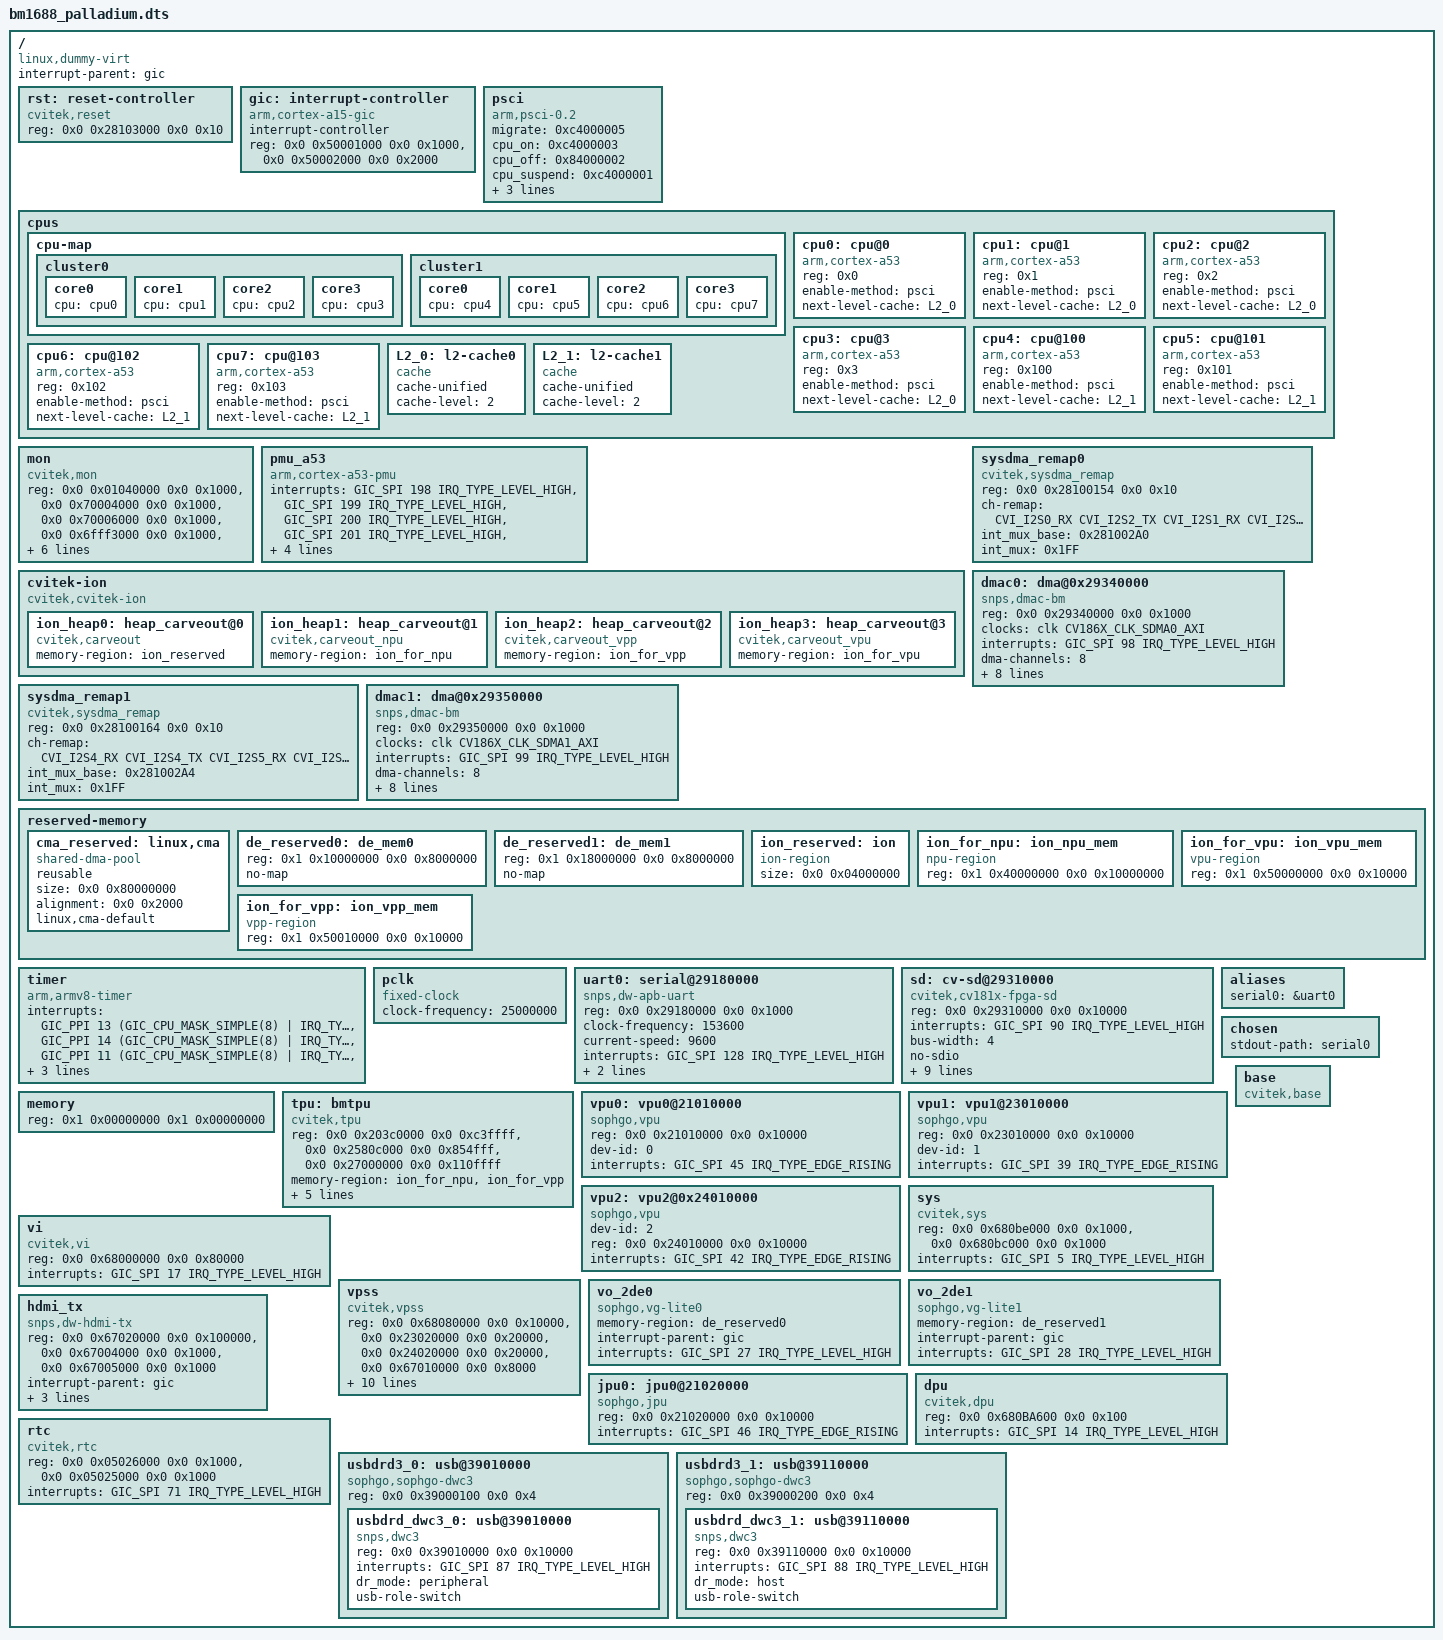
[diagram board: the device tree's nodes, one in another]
#include <dt-bindings/interrupt-controller/arm-gic.h>
#include <dt-bindings/gpio/gpio.h>
#include <dt-bindings/reset/cv186x-resets.h>
#include <dt-bindings/dma/cv186x-dmamap.h>

/dts-v1/;

/memreserve/	0x100000000 0x0000000000040000; // ATF BL31 + BL32
/memreserve/	0x200000000 0x0000000020000000; // ATF BL31 + BL32
/memreserve/	0x300000000 0x0000000003000000; // FW size: 48M

#include "soph-clocks.dtsi"
/ {
	compatible = "linux,dummy-virt";
	#size-cells = <0x2>;
	#address-cells = <0x2>;
	interrupt-parent = <&gic>;

	rst: reset-controller {
		#reset-cells = <1>;
		compatible = "cvitek,reset";
		reg = <0x0 0x28103000 0x0 0x10>;
	};

	gic: interrupt-controller {
		compatible = "arm,cortex-a15-gic";
		ranges;
		#size-cells = <0x2>;
		#address-cells = <0x2>;
		interrupt-controller;
		#interrupt-cells = <0x3>;
		reg = <0x0 0x50001000 0x0 0x1000>,
			  <0x0 0x50002000 0x0 0x2000>;
	};

	psci {
		migrate = <0xc4000005>;
		cpu_on = <0xc4000003>;
		cpu_off = <0x84000002>;
		cpu_suspend = <0xc4000001>;
		sys_poweroff = <0x84000008>;
		sys_reset = <0x84000009>;
		method = "smc";
		compatible = "arm,psci-0.2", "arm,psci";
	};

	cpus {
		#size-cells = <0x0>;
		#address-cells = <0x1>;

		cpu-map {
			cluster0 {
				core0 {
					cpu = <&cpu0>;
				};
				core1 {
					cpu = <&cpu1>;
				};
				core2 {
					cpu = <&cpu2>;
				};
				core3 {
					cpu = <&cpu3>;
				};
			};

			cluster1 {
				core0 {
					cpu = <&cpu4>;
				};
				core1 {
					cpu = <&cpu5>;
				};
				core2 {
					cpu = <&cpu6>;
				};
				core3 {
					cpu = <&cpu7>;
				};
			};
		};

		cpu0: cpu@0 {
			reg = <0x0>;
			enable-method = "psci";
			compatible = "arm,cortex-a53";
			device_type = "cpu";
			next-level-cache = <&L2_0>;
		};

		cpu1: cpu@1 {
			reg = <0x1>;
			enable-method = "psci";
			compatible = "arm,cortex-a53";
			device_type = "cpu";
			next-level-cache = <&L2_0>;
		};

		cpu2: cpu@2 {
			reg = <0x2>;
			enable-method = "psci";
			compatible = "arm,cortex-a53";
			device_type = "cpu";
			next-level-cache = <&L2_0>;
		};

		cpu3: cpu@3 {
			reg = <0x3>;
			enable-method = "psci";
			compatible = "arm,cortex-a53";
			device_type = "cpu";
			next-level-cache = <&L2_0>;
		};

		cpu4: cpu@100 {
			reg = <0x100>;
			enable-method = "psci";
			compatible = "arm,cortex-a53";
			device_type = "cpu";
			next-level-cache = <&L2_1>;
		};

		cpu5: cpu@101 {
			reg = <0x101>;
			enable-method = "psci";
			compatible = "arm,cortex-a53";
			device_type = "cpu";
			next-level-cache = <&L2_1>;
		};

		cpu6: cpu@102 {
			reg = <0x102>;
			enable-method = "psci";
			compatible = "arm,cortex-a53";
			device_type = "cpu";
			next-level-cache = <&L2_1>;
		};

		cpu7: cpu@103 {
			reg = <0x103>;
			enable-method = "psci";
			compatible = "arm,cortex-a53";
			device_type = "cpu";
			next-level-cache = <&L2_1>;
		};

		L2_0: l2-cache0 {
			compatible = "cache";
			cache-unified;
			cache-level = <2>;
		};

		L2_1: l2-cache1 {
			compatible = "cache";
			cache-unified;
			cache-level = <2>;
		};
	};

	mon {
		compatible = "cvitek,mon";
		reg-names = "pcmon", "ddr_ctrl", "ddr_phyd", "ddr_aximon_real", "ddr_aximon_offline", "ddr_aximon_bulk", "ddr_ddrmon_sys1", "ddr_ddrmon_sys2", "ddr_top";
		reg = <0x0 0x01040000 0x0 0x1000>,
					<0x0 0x70004000 0x0 0x1000>,
					<0x0 0x70006000 0x0 0x1000>,
					<0x0 0x6fff3000 0x0 0x1000>,
					<0x0 0x6fff4000 0x0 0x1000>,
					<0x0 0x6fff5000 0x0 0x1000>,
					<0x0 0x70008000 0x0 0x1000>,
					<0x0 0x78008000 0x0 0x1000>,
					<0x0 0x7000A000 0x0 0x1000>;
		interrupts = <GIC_SPI 77 IRQ_TYPE_EDGE_RISING>;
	};

	pmu_a53 {
		compatible = "arm,cortex-a53-pmu";
		interrupts = <GIC_SPI 198 IRQ_TYPE_LEVEL_HIGH>,
			     <GIC_SPI 199 IRQ_TYPE_LEVEL_HIGH>,
			     <GIC_SPI 200 IRQ_TYPE_LEVEL_HIGH>,
			     <GIC_SPI 201 IRQ_TYPE_LEVEL_HIGH>,
			     <GIC_SPI 211 IRQ_TYPE_LEVEL_HIGH>,
			     <GIC_SPI 212 IRQ_TYPE_LEVEL_HIGH>,
			     <GIC_SPI 213 IRQ_TYPE_LEVEL_HIGH>,
			     <GIC_SPI 214 IRQ_TYPE_LEVEL_HIGH>;
	};

	cvitek-ion {
		compatible = "cvitek,cvitek-ion";

		ion_heap0: heap_carveout@0 {
			compatible = "cvitek,carveout";
			memory-region = <&ion_reserved>;
		};
		#ifndef __UBOOT__
		ion_heap1: heap_carveout@1 {
			compatible = "cvitek,carveout_npu";
			memory-region = <&ion_for_npu>;
		};

		ion_heap2: heap_carveout@2 {
			compatible = "cvitek,carveout_vpp";
			memory-region = <&ion_for_vpp>;
		};

		ion_heap3: heap_carveout@3 {
			compatible = "cvitek,carveout_vpu";
			memory-region = <&ion_for_vpu>;
		};
		#endif
	};

	sysdma_remap0 {
		compatible = "cvitek,sysdma_remap";
		reg = <0x0 0x28100154 0x0 0x10>;
		ch-remap = <CVI_I2S0_RX CVI_I2S2_TX CVI_I2S1_RX CVI_I2S1_TX
					CVI_SPI_NAND CVI_SPI_NAND CVI_I2S2_RX CVI_I2S3_TX>;
		int_mux_base = <0x281002A0>;
		int_mux = <0x1FF>; /* enable bit [0..8] for CPU0(CA53) */
	};

	dmac0: dma@0x29340000 {
		compatible = "snps,dmac-bm";
		reg = <0x0 0x29340000 0x0 0x1000>;
		clock-names = "clk_sdma_axi";
		clocks = <&clk CV186X_CLK_SDMA0_AXI>;

		interrupts = <GIC_SPI 98 IRQ_TYPE_LEVEL_HIGH>;
		dma-channels = /bits/ 8 <8>;
		#dma-cells = <3>;
		dma-requests = /bits/ 8 <16>;
		chan_allocation_order = /bits/ 8 <0>;
		chan_priority = /bits/ 8 <1>;
		block_size = <1024>;
		dma-masters = /bits/ 8 <2>;
		data-width = <4 4>; /* bytes */
		axi_tr_width = <4>; /* bytes */
		block-ts = <15>;
	};

	sysdma_remap1 {
		compatible = "cvitek,sysdma_remap";
		reg = <0x0 0x28100164 0x0 0x10>;
		ch-remap = <CVI_I2S4_RX CVI_I2S4_TX CVI_I2S5_RX CVI_I2S5_TX
					CVI_SPI0_TX CVI_SPI0_TX CVI_SPI1_TX CVI_SPI1_TX>;
		int_mux_base = <0x281002A4>;
		int_mux = <0x1FF>; /* enable bit [0..8] for CPU0(CA53) */
	};

	dmac1: dma@0x29350000 {
		compatible = "snps,dmac-bm";
		reg = <0x0 0x29350000 0x0 0x1000>;
		clock-names = "clk_sdma_axi";
		clocks = <&clk CV186X_CLK_SDMA1_AXI>;

		interrupts = <GIC_SPI 99 IRQ_TYPE_LEVEL_HIGH>;
		dma-channels = /bits/ 8 <8>;
		#dma-cells = <3>;
		dma-requests = /bits/ 8 <16>;
		chan_allocation_order = /bits/ 8 <0>;
		chan_priority = /bits/ 8 <1>;
		block_size = <1024>;
		dma-masters = /bits/ 8 <2>;
		data-width = <4 4>; /* bytes */
		axi_tr_width = <4>; /* bytes */
		block-ts = <15>;
	};

	reserved-memory {
		#address-cells = <0x2>;
		#size-cells = <0x2>;
		ranges;

		cma_reserved: linux,cma {
			compatible = "shared-dma-pool";
			reusable;
			size = <0x0 0x80000000>; // 2GB
			alignment = <0x0 0x2000>; // 8KB
			linux,cma-default;
		};
		de_reserved0: de_mem0 {
				reg = <0x1 0x10000000 0x0 0x8000000>; // 128M, for 2de
				no-map;
		};
		de_reserved1: de_mem1 {
				reg = <0x1 0x18000000 0x0 0x8000000>; // 128M, for 2de
				no-map;
		};
		ion_reserved: ion {
			compatible = "ion-region";
			size = <0x0 0x04000000>; // 64MB
		};

		#ifndef __UBOOT__
		ion_for_npu: ion_npu_mem {
			compatible = "npu-region";
			reg = <0x1 0x40000000 0x0 0x10000000>; // 256M
		};

		ion_for_vpu: ion_vpu_mem {
			compatible = "vpu-region";
			reg = <0x1 0x50000000 0x0 0x10000>; // 1M, for VPU
		};

		ion_for_vpp: ion_vpp_mem {
			compatible = "vpp-region";
			reg = <0x1 0x50010000 0x0 0x10000>; // 1M, for VPP/JPU
		};
		#endif
	};

	timer {
		interrupts = <GIC_PPI 13 (GIC_CPU_MASK_SIMPLE(8) | IRQ_TYPE_LEVEL_LOW)>,
			<GIC_PPI 14 (GIC_CPU_MASK_SIMPLE(8) | IRQ_TYPE_LEVEL_LOW)>,
			<GIC_PPI 11 (GIC_CPU_MASK_SIMPLE(8) | IRQ_TYPE_LEVEL_LOW)>,
			<GIC_PPI 10 (GIC_CPU_MASK_SIMPLE(8) | IRQ_TYPE_LEVEL_LOW)>;
		always-on;
		clock-frequency = <25000000>;
		compatible = "arm,armv8-timer";
	};


	pclk: pclk {
		#clock-cells = <0>;
		compatible = "fixed-clock";
		clock-frequency = <25000000>;
	};

	uart0: serial@29180000 {
		compatible = "snps,dw-apb-uart";
		reg = <0x0 0x29180000 0x0 0x1000>;
		//clock-frequency = <10000000>;
		clock-frequency = <153600>;
		current-speed = <9600>;
		interrupts = <GIC_SPI 128 IRQ_TYPE_LEVEL_HIGH>;
		reg-shift = <2>;
		reg-io-width = <4>;
	};

#if 0
	gpio0: gpio@27010000 {
		compatible = "snps,dw-apb-gpio";
		reg = <0x0 0x27010000 0x0 0x1000>;
		#address-cells = <1>;
		#size-cells = <0>;

		porta: gpio-controller@0 {
			compatible = "snps,dw-apb-gpio-port";
			bank-name = "porta";
			gpio-controller;
			#gpio-cells = <2>;
			snps,nr-gpios = <32>;
			reg = <0>;
		};
	};

	gpio1: gpio@27011000 {
		compatible = "snps,dw-apb-gpio";
		reg = <0x0 0x27011000 0x0 0x1000>;
		#address-cells = <1>;
		#size-cells = <0>;

		portb: gpio-controller@1 {
			compatible = "snps,dw-apb-gpio-port";
			bank-name = "portb";
			gpio-controller;
			#gpio-cells = <2>;
			snps,nr-gpios = <32>;
			reg = <0>;
		};
	};

	gpio2: gpio@27012000 {
		compatible = "snps,dw-apb-gpio";
		reg = <0x0 0x27012000 0x0 0x1000>;
		#address-cells = <1>;
		#size-cells = <0>;

		portc: gpio-controller@2 {
			compatible = "snps,dw-apb-gpio-port";
			bank-name = "portc";
			gpio-controller;
			#gpio-cells = <2>;
			snps,nr-gpios = <32>;
			reg = <0>;
		};
	};

	gpio3: gpio@27013000 {
		compatible = "snps,dw-apb-gpio";
		reg = <0x0 0x27013000 0x0 0x1000>;
		#address-cells = <1>;
		#size-cells = <0>;

		portd: gpio-controller@3 {
			compatible = "snps,dw-apb-gpio-port";
			bank-name = "portd";
			gpio-controller;
			#gpio-cells = <2>;
			snps,nr-gpios = <32>;
			reg = <0>;
		};
	};

	gpio4: gpio@27014000 {
		compatible = "snps,dw-apb-gpio";
		reg = <0x0 0x27014000 0x0 0x1000>;
		#address-cells = <1>;
		#size-cells = <0>;

		porte: gpio-controller@4 {
			compatible = "snps,dw-apb-gpio-port";
			bank-name = "porte";
			gpio-controller;
			#gpio-cells = <2>;
			snps,nr-gpios = <32>;
			reg = <0>;
		};
	};

	gpio5: gpio@27015000 {
		compatible = "snps,dw-apb-gpio";
		reg = <0x0 0x27015000 0x0 0x1000>;
		#address-cells = <1>;
		#size-cells = <0>;

		portf: gpio-controller@5 {
			compatible = "snps,dw-apb-gpio-port";
			bank-name = "portf";
			gpio-controller;
			#gpio-cells = <2>;
			snps,nr-gpios = <32>;
			reg = <0>;
		};
	};

	eth_csrclk: eth_csrclk {
		clock-output-names = "eth_csrclk";
		clock-frequency = <250000000>;
		#clock-cells = <0x0>;
		compatible = "fixed-clock";
	};

	eth_ptpclk: eth_ptpclk {
		clock-output-names = "eth_ptpclk";
		clock-frequency = <50000000>;
		#clock-cells = <0x0>;
		compatible = "fixed-clock";
	};

	stmmac_axi_setup: stmmac-axi-config {
		snps,wr_osr_lmt = <1>;
		snps,rd_osr_lmt = <2>;
		snps,blen = <4 8 16 0 0 0 0>;
	};

	mtl_rx_setup: rx-queues-config {
		snps,rx-queues-to-use = <8>;
		queue0 {};
		queue1 {};
		queue2 {};
		queue3 {};
		queue4 {};
		queue5 {};
		queue6 {};
		queue7 {};
	};

	mtl_tx_setup: tx-queues-config {
		snps,tx-queues-to-use = <8>;
		queue0 {};
		queue1 {};
		queue2 {};
		queue3 {};
		queue4 {};
		queue5 {};
		queue6 {};
		queue7 {};
	};

	ethernet0: ethernet@290e0000 {
		compatible = "bitmain,ethernet";
		reg = <0x0 0x290e0000 0x0 0x4000>;
		reg-names = "mac";
		interrupt-names = "macirq";
		interrupts = <GIC_SPI 104 IRQ_TYPE_LEVEL_HIGH>;
		/*
		//bm1684x
		clock-names = "clk_tx", "gate_clk_tx", "stmmaceth", "ptp_ref", "gate_clk_ref";
		clocks = <&div_clk DIV_CLK_FPLL_TX_ETH0>,
			   <&div_clk GATE_CLK_ETH0_TX>,
			   <&div_clk GATE_CLK_AXI6_ETH0>,
			   <&div_clk GATE_CLK_PTP_REF_I_ETH0>,
			   <&div_clk GATE_CLK_REF_ETH0>;
		//cv183x
		clock-names = "stmmaceth", "ptp_ref", "clk_500m_eth", "clk_axi4_eth";
		clocks = <&eth_csrclk>, <&eth_ptpclk>, <&clk CV1835_CLK_500M_ETH0>, <&clk CV1835_CLK_AXI4_ETH0>;*/
		//cv182x
		clock-names = "stmmaceth", "ptp_ref";
		clocks = <&eth_csrclk>, <&eth_ptpclk>;
#ifdef __UBOOT__
		phy-reset-gpios = <&portd 21 0>;
#endif
		/* no hash filter and perfect filter support */
		snps,multicast-filter-bins = <0>;
		snps,perfect-filter-entries = <1>;

		snps,txpbl = <32>;
		snps,rxpbl = <32>;
		snps,aal;

		snps,axi-config = <&stmmac_axi_setup>;
		snps,mtl-rx-config = <&mtl_rx_setup>;
		snps,mtl-tx-config = <&mtl_tx_setup>;

		phy-mode = "rgmii-id";
		fixed-link {
			speed = <1000>;
			full-duplex;
		};
	};

	ethernet1: ethernet@290f0000 {
		compatible = "bitmain,ethernet";
		reg = <0x0 0x290f0000 0x0 0x4000>;
		reg-names = "mac";
		interrupt-names = "macirq";
		interrupts = <GIC_SPI 105 IRQ_TYPE_LEVEL_HIGH>;
		/*
		//bm1684x
		clock-names = "clk_tx", "gate_clk_tx", "stmmaceth", "ptp_ref", "gate_clk_ref";
		clocks = <&div_clk DIV_CLK_FPLL_TX_ETH0>,
			   <&div_clk GATE_CLK_ETH0_TX>,
			   <&div_clk GATE_CLK_AXI6_ETH0>,
			   <&div_clk GATE_CLK_PTP_REF_I_ETH0>,
			   <&div_clk GATE_CLK_REF_ETH0>;
		//cv183x
		clock-names = "stmmaceth", "ptp_ref", "clk_500m_eth", "clk_axi4_eth";
		clocks = <&eth_csrclk>, <&eth_ptpclk>, <&clk CV1835_CLK_500M_ETH0>, <&clk CV1835_CLK_AXI4_ETH0>;*/
		//cv182x
		clock-names = "stmmaceth", "ptp_ref";
		clocks = <&eth_csrclk>, <&eth_ptpclk>;
#ifdef __UBOOT__
		phy-reset-gpios = <&portd 22 0>;
#endif
		/* no hash filter and perfect filter support */
		snps,multicast-filter-bins = <0>;
		snps,perfect-filter-entries = <1>;

		snps,txpbl = <32>;
		snps,rxpbl = <32>;
		snps,aal;

		snps,axi-config = <&stmmac_axi_setup>;
		snps,mtl-rx-config = <&mtl_rx_setup>;
		snps,mtl-tx-config = <&mtl_tx_setup>;

		phy-mode = "rgmii-id";
		fixed-link {
			speed = <1000>;
			full-duplex;
		};
	};
#endif
	sd:cv-sd@29310000 {
	#ifndef __UBOOT__
		compatible = "cvitek,cv181x-fpga-sd";
	#else
		compatible = "cvitek,cv186x-sd";
	#endif
		reg = <0x0 0x29310000 0x0 0x10000>;
		reg-names = "core_mem";
		interrupts = <GIC_SPI 90 IRQ_TYPE_LEVEL_HIGH>;
		bus-width = <4>;
		//cap-sd-highspeed;
		//cap-mmc-highspeed;
		no-sdio;
		no-mmc;
		no-1-8-v;
		broken-cd;
		src-frequency = <5000000>;
		min-frequency = <200000>;
		max-frequency = <4000000>;
		reset_tx_rx_phy;
		reset-name = "sdhci";
		64_addressing;
	};

	memory {
		reg = <0x1 0x00000000 0x1 0x00000000>;	//4G
		device_type = "memory";
	};

	#ifndef __UBOOT__
	tpu: bmtpu {
		compatible = "cvitek,tpu";
		reg = <0x0 0x203c0000 0x0 0xc3ffff>,
			<0x0 0x2580c000 0x0 0x854fff>,
			<0x0 0x27000000 0x0 0x110ffff>;
		memory-region = <&ion_for_npu &ion_for_vpp>;
		sophgo_c906_fw_mode = <1>;
		interrupts = <GIC_SPI 85 IRQ_TYPE_LEVEL_HIGH>, <GIC_SPI 86 IRQ_TYPE_LEVEL_HIGH>,
		  	     <GIC_SPI 165 IRQ_TYPE_LEVEL_HIGH>, <GIC_SPI 166 IRQ_TYPE_LEVEL_HIGH>;
	};
        #endif

	aliases {
		serial0 = &uart0;
	};

	chosen {
		stdout-path = "serial0"; // "serial0:115200n8", no arguments means no re-initialization
	};

	vpu0: vpu0@21010000 {
		compatible = "sophgo,vpu";
		reg = 	<0x0 0x21010000 0x0 0x10000>;
		dev-id = <0>;
		interrupts = 	<GIC_SPI 45 IRQ_TYPE_EDGE_RISING>;
	};


	vpu1: vpu1@23010000 {
		compatible = "sophgo,vpu";
		reg = 	<0x0 0x23010000 0x0 0x10000>;
		dev-id = <1>;
		interrupts = 	<GIC_SPI 39 IRQ_TYPE_EDGE_RISING>;
	};


	vpu2: vpu2@0x24010000 {
		compatible = "sophgo,vpu";
		dev-id = <2>;
		reg = 	<0x0 0x24010000 0x0 0x10000>;
		interrupts = 	<GIC_SPI 42 IRQ_TYPE_EDGE_RISING>;
	};

	sys {
		compatible = "cvitek,sys";
		reg = <0x0 0x680be000 0x0 0x1000>,<0x0 0x680bc000 0x0 0x1000>;
		interrupts = <GIC_SPI 5 IRQ_TYPE_LEVEL_HIGH>;
		interrupt-names = "vi_cdma";
	};

	base {
		compatible = "cvitek,base";
	};

	vi {
		compatible = "cvitek,vi";
		reg = <0x0 0x68000000 0x0 0x80000>;
		interrupts = <GIC_SPI 17 IRQ_TYPE_LEVEL_HIGH>;
		interrupt-names = "isp";
	};

	vpss {
		compatible = "cvitek,vpss";
		reg =   <0x0 0x68080000 0x0 0x10000>,	//vpss_v
				<0x0 0x23020000 0x0 0x20000>,	//vpss_t0t1
				<0x0 0x24020000 0x0 0x20000>,	//vpss_t2t3
				<0x0 0x67010000 0x0 0x8000>;	//vpss_d
		interrupts = <GIC_SPI 23 IRQ_TYPE_LEVEL_HIGH>,
					<GIC_SPI 24 IRQ_TYPE_LEVEL_HIGH>,
					<GIC_SPI 25 IRQ_TYPE_LEVEL_HIGH>,
					<GIC_SPI 26 IRQ_TYPE_LEVEL_HIGH>,
					<GIC_SPI 40 IRQ_TYPE_LEVEL_HIGH>,
					<GIC_SPI 41 IRQ_TYPE_LEVEL_HIGH>,
					<GIC_SPI 43 IRQ_TYPE_LEVEL_HIGH>,
					<GIC_SPI 44 IRQ_TYPE_LEVEL_HIGH>,
					<GIC_SPI 31 IRQ_TYPE_LEVEL_HIGH>,
					<GIC_SPI 32 IRQ_TYPE_LEVEL_HIGH>;
		interrupt-names = "vpss_v0","vpss_v1","vpss_v2","vpss_v3",
						"vpss_t0","vpss_t1","vpss_t2","vpss_t3",
						"vpss_d0","vpss_d1";
	};

        vo_2de0 {
                compatible = "sophgo,vg-lite0";
                memory-region = <&de_reserved0>;
                interrupt-parent = <&gic>;
                interrupts = <GIC_SPI 27 IRQ_TYPE_LEVEL_HIGH>;
                interrupt-names = "vo_2de0";
        };

        vo_2de1 {
                compatible = "sophgo,vg-lite1";
                memory-region = <&de_reserved1>;
                interrupt-parent = <&gic>;
                interrupts = <GIC_SPI 28 IRQ_TYPE_LEVEL_HIGH>;
                interrupt-names = "vo_2de1";
        };

        hdmi_tx {
		compatible = "snps,dw-hdmi-tx";
		reg = <0x0 0x67020000 0x0 0x100000>,
		      <0x0 0x67004000 0x0 0x1000>,
		      <0x0 0x67005000 0x0 0x1000>;
		reg-names = "hdmi_tx", "disp0", "disp1";
		//clocks = <&clk CV181X_CLK_DISP_VIP>, <&clk CV181X_CLK_DSI_MAC_VIP>, <&clk CV181X_CLK_BT_VIP>;
		//clock-names = "clk_disp", "clk_dsi", "clk_bt";
		interrupt-parent = <&gic>;
		interrupts = <GIC_SPI 33 IRQ_TYPE_LEVEL_HIGH>,
			     <GIC_SPI 34 IRQ_TYPE_LEVEL_HIGH>,
			     <GIC_SPI 37 IRQ_TYPE_LEVEL_HIGH>;
		interrupt-names = "display0", "display1", "hdmi_tx";
	};

	jpu0: jpu0@21020000 {
		compatible = "sophgo,jpu";
		reg =  <0x0 0x21020000 0x0 0x10000>;
		interrupts =   <GIC_SPI 46 IRQ_TYPE_EDGE_RISING>;
	};

	dpu {
		compatible = "cvitek,dpu";
		reg = <0x0 0x680BA600 0x0 0x100>;
		interrupts = <GIC_SPI 14 IRQ_TYPE_LEVEL_HIGH>;
		interrupt-names = "dpu";
	};

	rtc {
		compatible = "cvitek,rtc";
		reg = <0x0 0x05026000 0x0 0x1000>,<0x0 0x05025000 0x0 0x1000>;
		//clocks = <&clk CV181X_CLK_RTC_25M>;
		//clock-names = "clk_rtc";
		interrupts = <GIC_SPI 71 IRQ_TYPE_LEVEL_HIGH>;
		interrupt-names = "rtc";
	};

	usbdrd3_0: usb@39010000 {
		compatible = "sophgo,sophgo-dwc3";
		reg = <0x0 0x39000100 0x0 0x4>;
		#address-cells = <2>;
		#size-cells = <2>;
		ranges;
		// clocks = <&cru SCLK_USB3OTG0_REF>, <&cru SCLK_USB3OTG0_SUSPEND>,
		// 	 <&cru ACLK_USB3OTG0>, <&cru ACLK_USB3_RKSOC_AXI_PERF>,
		// 	 <&cru ACLK_USB3>, <&cru ACLK_USB3_GRF>;
		// clock-names = "ref_clk", "suspend_clk",
		// 	      "bus_clk", "aclk_usb3_rksoc_axi_perf",
		// 	      "aclk_usb3", "grf_clk";
		// resets = <&cru SRST_A_USB3_OTG0>;
		// reset-names = "usb3-otg";
		status = "okay";

		usbdrd_dwc3_0: usb@39010000 {
			compatible = "snps,dwc3";
			reg = <0x0 0x39010000 0x0 0x10000>;
			interrupts = <GIC_SPI 87 IRQ_TYPE_LEVEL_HIGH>;
			dr_mode = "peripheral";
			usb-role-switch;
			status = "okay";
		};
	};

	usbdrd3_1: usb@39110000 {
		compatible = "sophgo,sophgo-dwc3";
		reg = <0x0 0x39000200 0x0 0x4>;
		#address-cells = <2>;
		#size-cells = <2>;
		ranges;
		// clocks = <&cru SCLK_USB3OTG1_REF>, <&cru SCLK_USB3OTG1_SUSPEND>,
		// 	 <&cru ACLK_USB3OTG1>, <&cru ACLK_USB3_RKSOC_AXI_PERF>,
		// 	 <&cru ACLK_USB3>, <&cru ACLK_USB3_GRF>;
		// clock-names = "ref_clk", "suspend_clk",
		// 	      "bus_clk", "aclk_usb3_rksoc_axi_perf",
		// 	      "aclk_usb3", "grf_clk";
		// resets = <&cru SRST_A_USB3_OTG1>;
		// reset-names = "usb3-otg";
		status = "okay";

		usbdrd_dwc3_1: usb@39110000 {
			compatible = "snps,dwc3";
			reg = <0x0 0x39110000 0x0 0x10000>;
			interrupts = <GIC_SPI 88 IRQ_TYPE_LEVEL_HIGH>;
			dr_mode = "host";
			usb-role-switch;
			status = "okay";
		};
	};
};

